# AM13E23219 register map
Vendor: Texas Instruments; File version: 1.0
CPU: CM33 r0p1, little endian, MPU, FPU, VTOR, 4 interrupt priority bits
Registers are 32-bit, read-write, reset 0x0 unless marked. A register's access mark holds for its fields unless they carry their own. Offsets are from the block's base; [hi:lo] are bit positions; lines under a group give offsets from that group; {n}, {i} and the like mark numbered series; 'fields as' and 'values as' point back to an identical list.

## ETPWM0 — EPWM module
Base 0x400B4000
Same registers: ETPWM1 0x400B5000, ETPWM2 0x400B6000, ETPWM3 0x400B7000, ETPWM4 0x400B8000, ETPWM5 0x400B9000
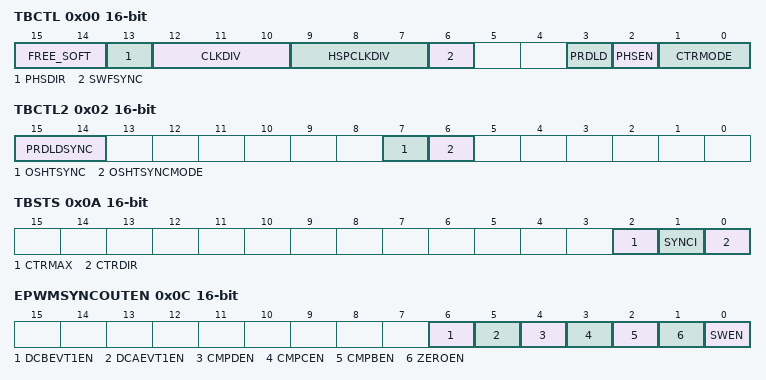
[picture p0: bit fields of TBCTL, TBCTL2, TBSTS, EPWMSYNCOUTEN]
0x00 TBCTL 16-bit — Time Base Control Register
  [15:14] FREE_SOFT — Emulation Mode Bits
  [13] PHSDIR — Phase Direction Bit
  [12:10] CLKDIV — Time Base Clock Pre-scaler
  [9:7] HSPCLKDIV — High Speed TBCLK Pre-scaler
  [6] SWFSYNC — Software Force Sync Pulse
  [3] PRDLD — Active Period Load
  [2] PHSEN — Phase Load Enable
  [1:0] CTRMODE — Counter Mode
0x02 TBCTL2 16-bit — Time Base Control Register 2
  [15:14] PRDLDSYNC — PRD Shadow to Active Load on SYNC Event
  [7] OSHTSYNC — One shot sync
  [6] OSHTSYNCMODE — One shot sync mode
0x06 EPWMSYNCINSEL 16-bit — EPWMxSYNCIN Source Select Register
  [4:0] SEL — EPWMxSYNCI source select
0x08 TBCTR 16-bit access not given — Time Base Counter Register
0x0A TBSTS 16-bit access per field — Time Base Status Register
  [2] CTRMAX rw — Counter Max Latched Status
  [1] SYNCI rw — External Input Sync Status
  [0] CTRDIR ro — Counter Direction Status
0x0C EPWMSYNCOUTEN 16-bit — EPWMxSYNCOUT Source Enable Register
  [6] DCBEVT1EN — EPWMxSYNCO Digital Compare B Event 1 Sync Enable
  [5] DCAEVT1EN — EPWMxSYNCO Digital Compare A Event 1 Sync Enable
  [4] CMPDEN — EPWMxSYNCO Compare D Event Enable
  [3] CMPCEN — EPWMxSYNCO Compare C Event Enable
  [2] CMPBEN — EPWMxSYNCO Compare B Event Enable
  [1] ZEROEN — EPWMxSYNCO Zero Count Event Enable
  [0] SWEN — EPWMxSYNCO Software Force Enable
0x0E TBCTL3 16-bit — Time Base Control Register 3
  [0] OSSFRCEN — One Shot Sync Force Enable
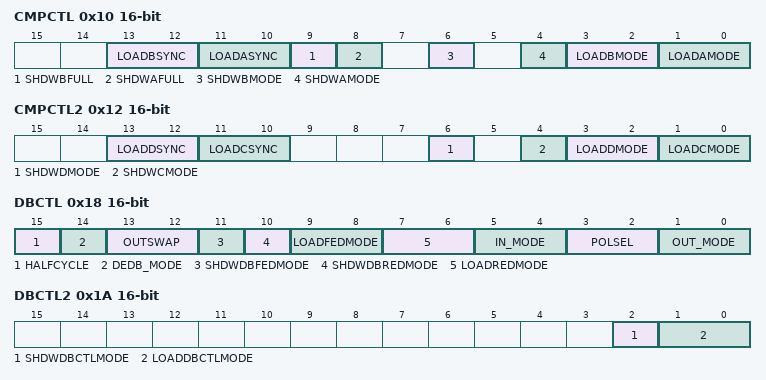
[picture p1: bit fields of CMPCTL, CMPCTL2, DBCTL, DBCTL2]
0x10 CMPCTL 16-bit access per field — Counter Compare Control Register
  [13:12] LOADBSYNC rw — Active Compare B Load on SYNC
  [11:10] LOADASYNC rw — Active Compare A Load on SYNC
  [9] SHDWBFULL ro — Compare B Shadow Register Full Status
  [8] SHDWAFULL ro — Compare A Shadow Register Full Status
  [6] SHDWBMODE rw — Compare B Register Block Operating Mode
  [4] SHDWAMODE rw — Compare A Register Block Operating Mode
  [3:2] LOADBMODE rw — Active Compare B Load
  [1:0] LOADAMODE rw — Active Compare A Load
0x12 CMPCTL2 16-bit — Counter Compare Control Register 2
  [13:12] LOADDSYNC — Active Compare D Load on SYNC
  [11:10] LOADCSYNC — Active Compare C Load on SYNC
  [6] SHDWDMODE — Compare D Block Operating Mode
  [4] SHDWCMODE — Compare C Block Operating Mode
  [3:2] LOADDMODE — Active Compare D load
  [1:0] LOADCMODE — Active Compare C Load
0x18 DBCTL 16-bit — Dead-Band Generator Control Register
  [15] HALFCYCLE — Half Cycle Clocking Enable
  [14] DEDB_MODE — Dead Band Dual-Edge B Mode Control
  [13:12] OUTSWAP — Dead Band Output Swap Control
  [11] SHDWDBFEDMODE — DBFED Block Operating Mode
  [10] SHDWDBREDMODE — DBRED Block Operating Mode
  [9:8] LOADFEDMODE — Active DBFED Load Mode
  [7:6] LOADREDMODE — Active DBRED Load Mode
  [5:4] IN_MODE — Dead Band Input Select Mode Control
  [3:2] POLSEL — Polarity Select Control
  [1:0] OUT_MODE — Dead Band Output Mode Control
0x1A DBCTL2 16-bit — Dead-Band Generator Control Register 2
  [2] SHDWDBCTLMODE — DBCTL Load mode Select
  [1:0] LOADDBCTLMODE — DBCTL Load from Shadow Mode Select
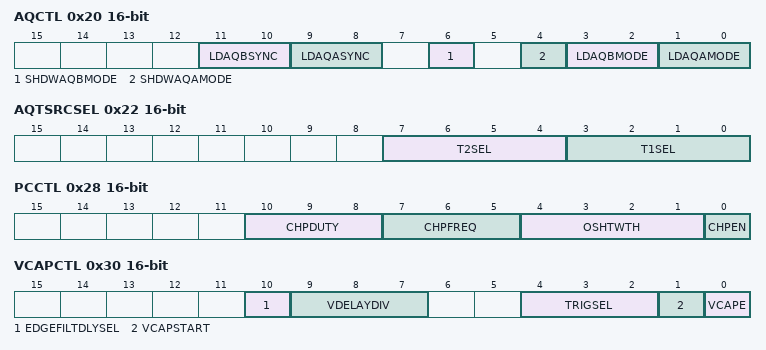
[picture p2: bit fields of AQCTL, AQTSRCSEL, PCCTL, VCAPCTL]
0x20 AQCTL 16-bit — Action Qualifier Control Register
  [11:10] LDAQBSYNC — AQCTLB Register Load on SYNC
  [9:8] LDAQASYNC — AQCTLA Register Load on SYNC
  [6] SHDWAQBMODE — Action Qualifier B Operating Mode
  [4] SHDWAQAMODE — Action Qualifer A Operating Mode
  [3:2] LDAQBMODE — Action Qualifier B Load Select
  [1:0] LDAQAMODE — Action Qualifier A Load Select
0x22 AQTSRCSEL 16-bit — Action Qualifier Trigger Event Source Select Register
  [7:4] T2SEL — T2 Event Source Select Bits
  [3:0] T1SEL — T1 Event Source Select Bits
0x28 PCCTL 16-bit — PWM Chopper Control Register
  [10:8] CHPDUTY — Chopping clock Duty cycle
  [7:5] CHPFREQ — Chopping clock frequency
  [4:1] OSHTWTH — One-shot pulse width
  [0] CHPEN — PWM chopping enable
0x30 VCAPCTL 16-bit — Valley Capture Control Register
  [10] EDGEFILTDLYSEL — Valley Switching Mode Delay Select
  [9:7] VDELAYDIV — Valley Delay Mode Divide Enable
  [4:2] TRIGSEL — Capture Trigger Select
  [1] VCAPSTART — Valley Capture Start
  [0] VCAPE — Valley Capture mode
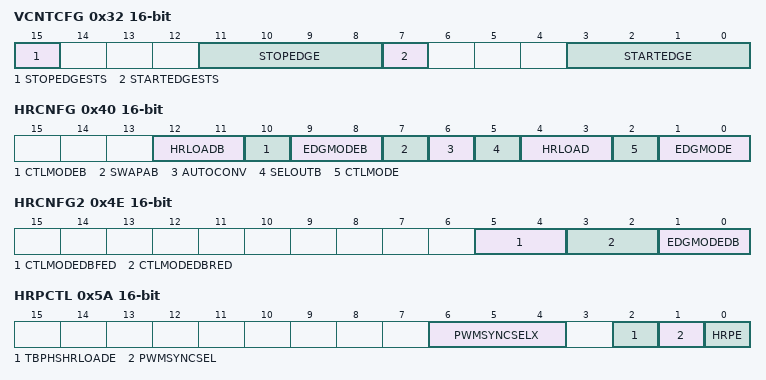
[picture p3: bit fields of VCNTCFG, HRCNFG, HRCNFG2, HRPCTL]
0x32 VCNTCFG 16-bit access per field — Valley Counter Config Register
  [15] STOPEDGESTS ro — Stop Edge Status Bit
  [11:8] STOPEDGE rw — Counter Start Edge Selection
  [7] STARTEDGESTS ro — Start Edge Status Bit
  [3:0] STARTEDGE rw — Counter Start Edge Selection
0x40 HRCNFG 16-bit — HRPWM Configuration Register
  [12:11] HRLOADB — ePWMxB Shadow Mode Select Bits
  [10] CTLMODEB — ePWMxB Control Mode Select Bits
  [9:8] EDGMODEB — ePWMxB Edge Mode Select Bits
  [7] SWAPAB — Swap EPWMA and EPWMB Outputs Bit
  [6] AUTOCONV — Autoconversion Bit
  [5] SELOUTB — EPWMB Output Selection Bit
  [4:3] HRLOAD — ePWMxA Shadow Mode Select Bits
  [2] CTLMODE — ePWMxA Control Mode Select Bits
  [1:0] EDGMODE — ePWMxA Edge Mode Select Bits
0x42 HRPWR 16-bit — HRPWM Power Register
  [15] CALPWRON — Calibration Power On
0x4C HRMSTEP 16-bit — HRPWM MEP Step Register
  [7:0] HRMSTEP — High Resolution Micro Step Value
0x4E HRCNFG2 16-bit — HRPWM Configuration 2 Register
  [5:4] CTLMODEDBFED — DBFED Control Mode Select Bits
  [3:2] CTLMODEDBRED — DBRED Control Mode Select Bits
  [1:0] EDGMODEDB — Dead-Band Edge-Mode Select Bits
0x5A HRPCTL 16-bit — High Resolution Period Control Register
  [6:4] PWMSYNCSELX — EPWMSYNCPER Extended Source Select Bit:
  [2] TBPHSHRLOADE — TBPHSHR Load Enable
  [1] PWMSYNCSEL — EPWMSYNCPER Source Select
  [0] HRPE — High Resolution Period Enable
0x5C TRREM 16-bit — HRPWM High Resolution Remainder Register
  [10:0] TRREM — HRPWM Remainder Bits
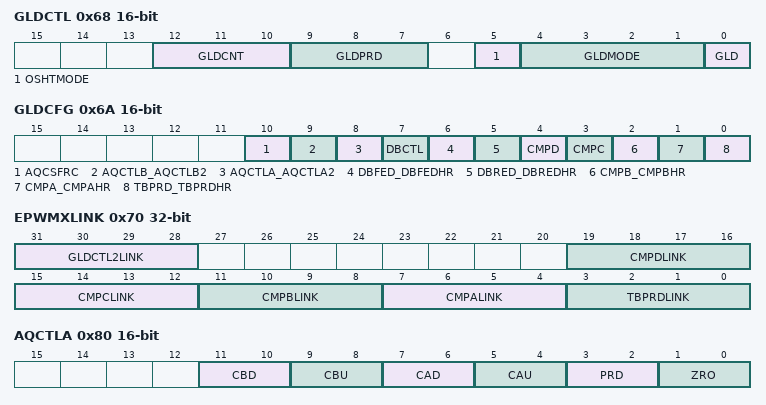
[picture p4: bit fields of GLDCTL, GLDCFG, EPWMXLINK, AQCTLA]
0x68 GLDCTL 16-bit access per field — Global PWM Load Control Register
  [12:10] GLDCNT ro — Global Load Strobe Counter Register
  [9:7] GLDPRD rw — Global Load Strobe Period Select Register
  [5] OSHTMODE rw — One Shot Load mode control bit
  [4:1] GLDMODE rw — Shadow to Active Global Load Pulse Selection
  [0] GLD rw — Global Shadow to Active load event control
0x6A GLDCFG 16-bit — Global PWM Load Config Register
  [10] AQCSFRC — Global load event configuration for AQCSFRC
  [9] AQCTLB_AQCTLB2 — Global load event configuration for AQCTLB/B2
  [8] AQCTLA_AQCTLA2 — Global load event configuration for AQCTLA/A2
  [7] DBCTL — Global load event configuration for DBCTL
  [6] DBFED_DBFEDHR — Global load event configuration for DBFED:DBFEDHR
  [5] DBRED_DBREDHR — Global load event configuration for DBRED:DBREDHR
  [4] CMPD — Global load event configuration for CMPD
  [3] CMPC — Global load event configuration for CMPC
  [2] CMPB_CMPBHR — Global load event configuration for CMPB:CMPBHR
  [1] CMPA_CMPAHR — Global load event configuration for CMPA:CMPAHR
  [0] TBPRD_TBPRDHR — Global load event configuration for TBPRD:TBPRDHR
0x70 EPWMXLINK
  [31:28] GLDCTL2LINK
  [19:16] CMPDLINK
  [15:12] CMPCLINK
  [11:8] CMPBLINK — CMPB:CMPBHR Link
  [7:4] CMPALINK — CMPA:CMPAHR Link
  [3:0] TBPRDLINK — TBPRD:TBPRDHR Link
0x80 AQCTLA 16-bit — Action Qualifier Control Register For Output A
  [11:10] CBD — Action Counter = Compare B Down
  [9:8] CBU — Action Counter = Compare B Up
  [7:6] CAD — Action Counter = Compare A Down
  [5:4] CAU — Action Counter = Compare A Up
  [3:2] PRD — Action Counter = Period
  [1:0] ZRO — Action Counter = Zero
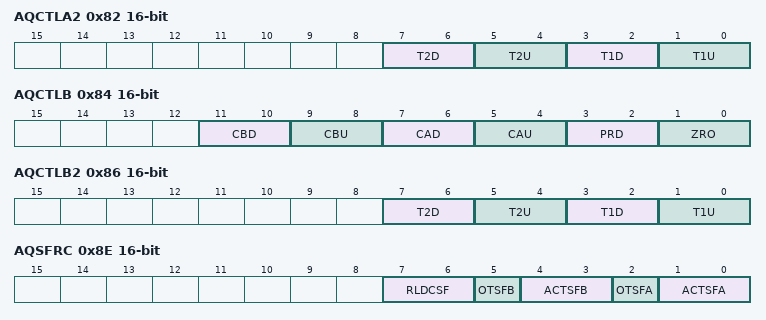
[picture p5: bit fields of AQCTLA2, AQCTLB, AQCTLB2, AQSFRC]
0x82 AQCTLA2 16-bit — Additional Action Qualifier Control Register For Output A
  [7:6] T2D — Action when event occurs on T2 in DOWN-Count
  [5:4] T2U — Action when event occurs on T2 in UP-Count
  [3:2] T1D — Action when event occurs on T1 in DOWN-Count
  [1:0] T1U — Action when event occurs on T1 in UP-Count
0x84 AQCTLB 16-bit — Action Qualifier Control Register For Output B
  fields as AQCTLA
0x86 AQCTLB2 16-bit — Additional Action Qualifier Control Register For Output B
  fields as AQCTLA2
0x8E AQSFRC 16-bit — Action Qualifier Software Force Register
  [7:6] RLDCSF — Reload from Shadow Options
  [5] OTSFB — One-time SW Force A Output
  [4:3] ACTSFB — Action when One-time SW Force B Invoked
  [2] OTSFA — One-time SW Force A Output
  [1:0] ACTSFA — Action when One-time SW Force A Invoked
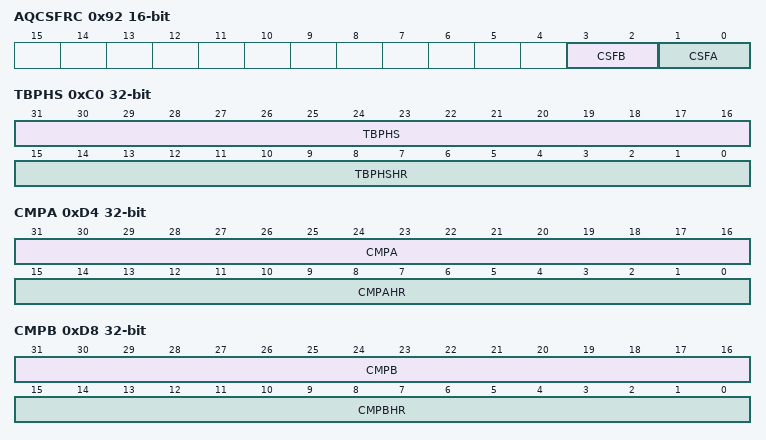
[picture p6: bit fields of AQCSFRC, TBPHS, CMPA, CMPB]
0x92 AQCSFRC 16-bit — Action Qualifier Continuous S/W Force Register
  [3:2] CSFB — Continuous Software Force on output B
  [1:0] CSFA — Continuous Software Force on output A
0xA0 DBREDHR 16-bit — Dead-Band Generator Rising Edge Delay High Resolution Mirror Register
  [15:9] DBREDHR — DBREDHR High Resolution Bits
0xA2 DBRED 16-bit — Dead-Band Generator Rising Edge Delay High Resolution Mirror Register
  [13:0] DBRED — Rising edge delay value
0xA4 DBFEDHR 16-bit — Dead-Band Generator Falling Edge Delay High Resolution Register
  [15:9] DBFEDHR — DBFEDHR High Resolution Bits
0xA6 DBFED 16-bit — Dead-Band Generator Falling Edge Delay Count Register
  [13:0] DBFED — Falling edge delay value
0xC0 TBPHS — Time Base Phase High
  [31:16] TBPHS — Phase Offset Register
  [15:0] TBPHSHR — Extension Register for HRPWM Phase (8-bits)
0xC4 TBPRDHR 16-bit — Time Base Period High Resolution Register
  [15:8] TBPRDHR — High res Time base period register
0xC6 TBPRD 16-bit access not given — Time Base Period Register
0xD4 CMPA — Counter Compare A Register
  [31:16] CMPA — Compare A Register
  [15:0] CMPAHR — Compare A HRPWM Extension Register
0xD8 CMPB — Compare B Register
  [31:16] CMPB — Compare B Register
  [15:0] CMPBHR — Compare B High Resolution Bits
0xDE CMPC 16-bit access not given — Counter Compare C Register
0xE2 CMPD 16-bit access not given — Counter Compare D Register
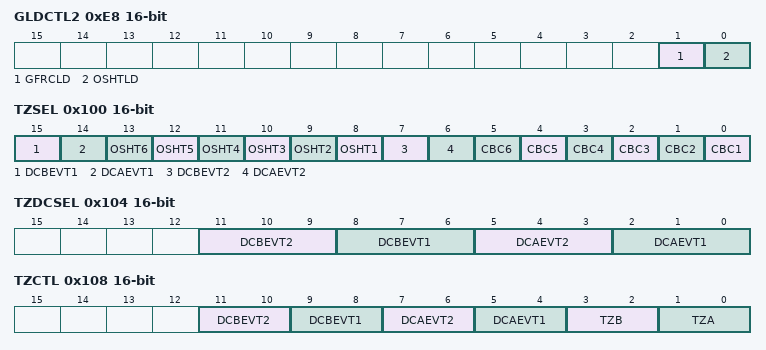
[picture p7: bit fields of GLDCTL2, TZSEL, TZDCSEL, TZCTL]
0xE8 GLDCTL2 16-bit — Global PWM Load Control Register 2
  [1] GFRCLD — Force reload event in one shot mode
  [0] OSHTLD — Enable reload event in one shot mode
0xEE SWVDELVAL 16-bit access not given — Software Valley Mode Delay Register
0x100 TZSEL 16-bit — Trip Zone Select Register
  [15] DCBEVT1 — One-shot DCBEVT1 select
  [14] DCAEVT1 — One-shot DCAEVT1 select
  [n+7] OSHT{n} (n=1..6) — One-shot TZ{n} select
  [7] DCBEVT2 — DCBEVT2 CBC select
  [6] DCAEVT2 — DCAEVT2 CBC select
  [n-1] CBC{n} (n=1..6) — TZ{n} CBC select
0x104 TZDCSEL 16-bit — Trip Zone Digital Comparator Select Register
  [11:9] DCBEVT2 — Digital Compare Output B Event 2
  [8:6] DCBEVT1 — Digital Compare Output B Event 1
  [5:3] DCAEVT2 — Digital Compare Output A Event 2
  [2:0] DCAEVT1 — Digital Compare Output A Event 1
0x108 TZCTL 16-bit — Trip Zone Control Register
  [11:10] DCBEVT2 — EPWMxB action on DCBEVT2
  [9:8] DCBEVT1 — EPWMxB action on DCBEVT1
  [7:6] DCAEVT2 — EPWMxA action on DCAEVT2
  [5:4] DCAEVT1 — EPWMxA action on DCAEVT1
  [3:2] TZB — TZ1 to TZ6 Trip Action On EPWMxB
  [1:0] TZA — TZ1 to TZ6 Trip Action On EPWMxA
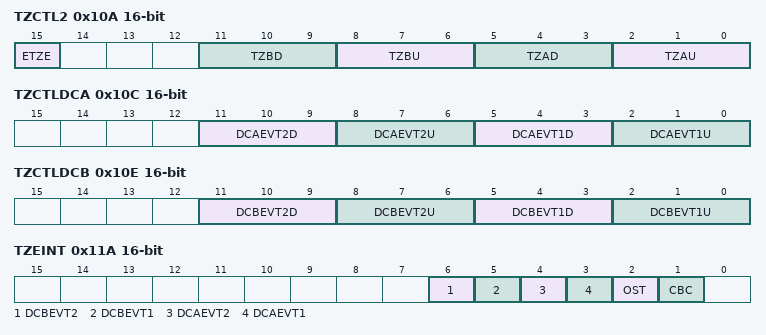
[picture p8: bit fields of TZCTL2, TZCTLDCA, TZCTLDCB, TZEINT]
0x10A TZCTL2 16-bit — Additional Trip Zone Control Register
  [15] ETZE — TZCTL2 Enable
  [11:9] TZBD — Trip Action On EPWMxB while Count direction is DOWN
  [8:6] TZBU — Trip Action On EPWMxB while Count direction is UP
  [5:3] TZAD — Trip Action On EPWMxA while Count direction is DOWN
  [2:0] TZAU — Trip Action On EPWMxA while Count direction is UP
0x10C TZCTLDCA 16-bit — Trip Zone Control Register Digital Compare A
  [11:9] DCAEVT2D — DCAEVT2 Action On EPWMxA while Count direction is DOWN
  [8:6] DCAEVT2U — DCAEVT2 Action On EPWMxA while Count direction is UP
  [5:3] DCAEVT1D — DCAEVT1 Action On EPWMxA while Count direction is DOWN
  [2:0] DCAEVT1U — DCAEVT1 Action On EPWMxA while Count direction is UP
0x10E TZCTLDCB 16-bit — Trip Zone Control Register Digital Compare B
  [11:9] DCBEVT2D — DCBEVT2 Action On EPWMxA while Count direction is DOWN
  [8:6] DCBEVT2U — DCBEVT2 Action On EPWMxA while Count direction is UP
  [5:3] DCBEVT1D — DCBEVT1 Action On EPWMxA while Count direction is DOWN
  [2:0] DCBEVT1U — DCBEVT1 Action On EPWMxA while Count direction is UP
0x11A TZEINT 16-bit — Trip Zone Enable Interrupt Register
  [6] DCBEVT2 — Digital Compare B Event 2 Int Enable
  [5] DCBEVT1 — Digital Compare B Event 1 Int Enable
  [4] DCAEVT2 — Digital Compare A Event 2 Int Enable
  [3] DCAEVT1 — Digital Compare A Event 1 Int Enable
  [2] OST — Trip Zones One Shot Int Enable
  [1] CBC — Trip Zones Cycle By Cycle Int Enable
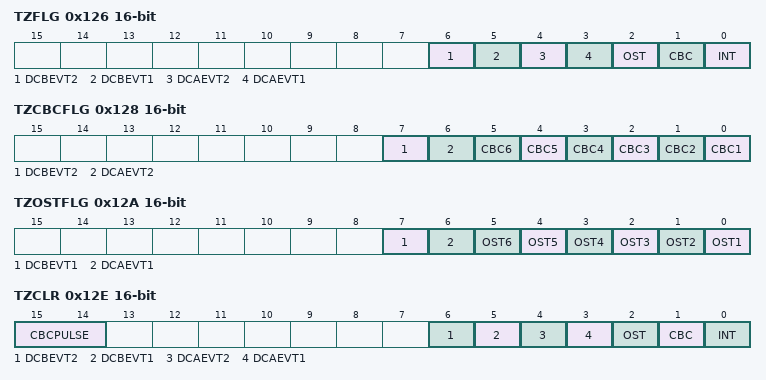
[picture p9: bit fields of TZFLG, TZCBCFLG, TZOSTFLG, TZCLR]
0x126 TZFLG 16-bit ro — Trip Zone Flag Register
  [6] DCBEVT2 — Digital Compare B Event 2 Flag
  [5] DCBEVT1 — Digital Compare B Event 1 Flag
  [4] DCAEVT2 — Digital Compare A Event 2 Flag
  [3] DCAEVT1 — Digital Compare A Event 1 Flag
  [2] OST — Trip Zones One Shot Flag
  [1] CBC — Trip Zones Cycle By Cycle Flag
  [0] INT — Global Int Status Flag
0x128 TZCBCFLG 16-bit ro — Trip Zone CBC Flag Register
  [7] DCBEVT2 — Latched Status Flag for Digital Compare Output B Event 2
  [6] DCAEVT2 — Latched Status Flag for Digital Compare Output A Event 2
  [n-1] CBC{n} (n=1..6) — Latched Status Flag for CBC{n} Trip Latch
0x12A TZOSTFLG 16-bit ro — Trip Zone OST Flag Register
  [7] DCBEVT1 — Latched Status Flag for Digital Compare Output B Event 1
  [6] DCAEVT1 — Latched Status Flag for Digital Compare Output A Event 1
  [n-1] OST{n} (n=1..6) — Latched Status Flag for OST{n} Trip Latch
0x12E TZCLR 16-bit — Trip Zone Clear Register
  [15:14] CBCPULSE — Clear Pulse for CBC Trip Latch
  [6] DCBEVT2 — DCBEVT2 Flag Clear
  [5] DCBEVT1 — DCBEVT1 Flag Clear
  [4] DCAEVT2 — DCAEVT2 Flag Clear
  [3] DCAEVT1 — DCAVET1 Flag Clear
  [2] OST — One-Shot Flag Clear
  [1] CBC — Cycle-By-Cycle Flag Clear
  [0] INT — Global Interrupt Clear Flag
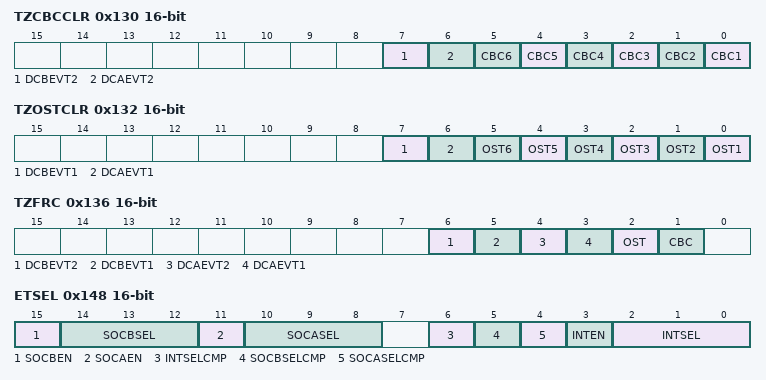
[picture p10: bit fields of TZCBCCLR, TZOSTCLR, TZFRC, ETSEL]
0x130 TZCBCCLR 16-bit — Trip Zone CBC Clear Register
  [7] DCBEVT2 — Clear Flag for DCBEVT2 selected for CBC
  [6] DCAEVT2 — Clear Flag forDCAEVT2 selected for CBC
  [n-1] CBC{n} (n=1..6) — Clear Flag for Cycle-By-Cycle (CBC{n}) Trip Latch
0x132 TZOSTCLR 16-bit — Trip Zone OST Clear Register
  [7] DCBEVT1 — Clear Flag for DCBEVT1 selected for OST
  [6] DCAEVT1 — Clear Flag for DCAEVT1 selected for OST
  [n-1] OST{n} (n=1..6) — Clear Flag for Oneshot (OST{n}) Trip Latch
0x136 TZFRC 16-bit — Trip Zone Force Register
  [6] DCBEVT2 — Force Digital Compare B Event 2
  [5] DCBEVT1 — Force Digital Compare B Event 1
  [4] DCAEVT2 — Force Digital Compare A Event 2
  [3] DCAEVT1 — Force Digital Compare A Event 1
  [2] OST — Force Trip Zones One Shot Event
  [1] CBC — Force Trip Zones Cycle By Cycle Event
0x148 ETSEL 16-bit — Event Trigger Selection Register
  [15] SOCBEN — Start of Conversion B Enable
  [14:12] SOCBSEL — Start of Conversion B Select
  [11] SOCAEN — Start of Conversion A Enable
  [10:8] SOCASEL — Start of Conversion A Select
  [6] INTSELCMP — EPWMxINT Compare Select
  [5] SOCBSELCMP — EPWMxSOCB Compare Select
  [4] SOCASELCMP — EPWMxSOCA Compare Select
  [3] INTEN — EPWMxINTn Enable
  [2:0] INTSEL — EPWMxINTn Select
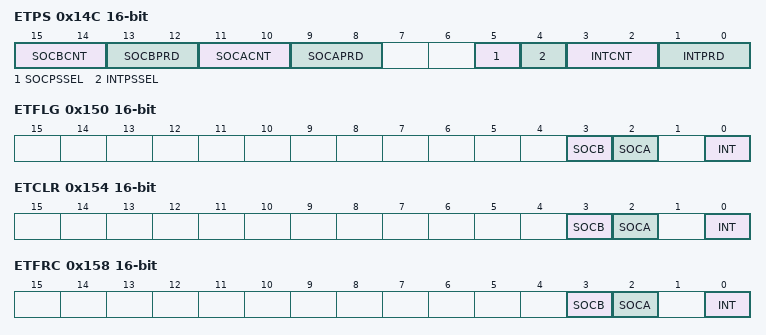
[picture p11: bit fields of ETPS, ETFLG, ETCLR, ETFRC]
0x14C ETPS 16-bit access per field — Event Trigger Pre-Scale Register
  [15:14] SOCBCNT ro — EPWMxSOCB Counter
  [13:12] SOCBPRD rw — EPWMxSOCB Period Select
  [11:10] SOCACNT ro — EPWMxSOCA Counter Register
  [9:8] SOCAPRD rw — EPWMxSOCA Period Select
  [5] SOCPSSEL rw — EPWMxSOC A/B Pre-Scale Selection Bits
  [4] INTPSSEL rw — EPWMxINTn Pre-Scale Selection Bits
  [3:2] INTCNT ro — EPWMxINTn Counter Register
  [1:0] INTPRD rw — EPWMxINTn Period Select
0x150 ETFLG 16-bit ro — Event Trigger Flag Register
  [3] SOCB — EPWMxSOCB Flag
  [2] SOCA — EPWMxSOCA Flag
  [0] INT — EPWMxINTn Flag
0x154 ETCLR 16-bit — Event Trigger Clear Register
  [3] SOCB — EPWMxSOCB Clear
  [2] SOCA — EPWMxSOCA Clear
  [0] INT — EPWMxINTn Clear
0x158 ETFRC 16-bit — Event Trigger Force Register
  [3] SOCB — EPWMxSOCB Force
  [2] SOCA — EPWMxSOCA Force
  [0] INT — EPWMxINTn Force
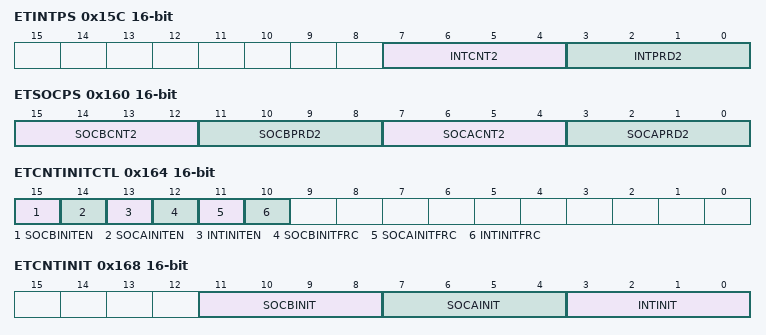
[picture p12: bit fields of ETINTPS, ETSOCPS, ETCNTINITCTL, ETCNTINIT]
0x15C ETINTPS 16-bit access per field — Event-Trigger Interrupt Pre-Scale Register
  [7:4] INTCNT2 ro — EPWMxINTn Counter Register
  [3:0] INTPRD2 rw — EPWMxINTn Period Select
0x160 ETSOCPS 16-bit access per field — Event-Trigger SOC Pre-Scale Register
  [15:12] SOCBCNT2 ro — EPWMxSOCB Counter Register
  [11:8] SOCBPRD2 rw — EPWMxSOCB Period Select
  [7:4] SOCACNT2 ro — EPWMxSOCA Counter Register
  [3:0] SOCAPRD2 rw — EPWMxSOCA Period Select
0x164 ETCNTINITCTL 16-bit — Event-Trigger Counter Initialization Control Register
  [15] SOCBINITEN — EPWMxSOCB Counter Initialization Enable
  [14] SOCAINITEN — EPWMxSOCA Counter Initialization Enable
  [13] INTINITEN — EPWMxINT Counter Initialization Enable
  [12] SOCBINITFRC — EPWMxSOCB Counter Initialization Force
  [11] SOCAINITFRC — EPWMxSOCA Counter Initialization Force
  [10] INTINITFRC — EPWMxINT Counter Initialization Force
0x168 ETCNTINIT 16-bit — Event-Trigger Counter Initialization Register
  [11:8] SOCBINIT — EPWMxSOCB Counter Initialization Bits
  [7:4] SOCAINIT — EPWMxSOCA Counter Initialization Bits
  [3:0] INTINIT — EPWMxINT Counter Initialization Bits
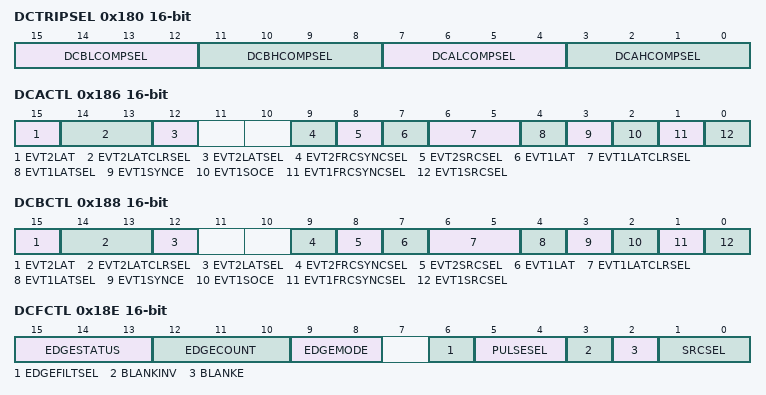
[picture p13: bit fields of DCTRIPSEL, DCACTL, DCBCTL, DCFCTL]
0x180 DCTRIPSEL 16-bit — Digital Compare Trip Select Register
  [15:12] DCBLCOMPSEL — Digital Compare B Low COMP Input Select
  [11:8] DCBHCOMPSEL — Digital Compare B High COMP Input Select
  [7:4] DCALCOMPSEL — Digital Compare A Low COMP Input Select
  [3:0] DCAHCOMPSEL — Digital Compare A High COMP Input Select
0x186 DCACTL 16-bit access per field — Digital Compare A Control Register
  [15] EVT2LAT ro — Indicates the status of DCAEVT2LAT signal.
  [14:13] EVT2LATCLRSEL rw — DCAEVT2 Latched clear source select
  [12] EVT2LATSEL rw — DCAEVT2 Latched signal select
  [9] EVT2FRCSYNCSEL rw — DCAEVT2 Force Sync Signal
  [8] EVT2SRCSEL rw — DCAEVT2 Source Signal
  [7] EVT1LAT ro — Indicates the status of DCAEVT1LAT signal.
  [6:5] EVT1LATCLRSEL rw — DCAEVT1 Latched clear source select
  [4] EVT1LATSEL rw — DCAEVT1 Latched signal select
  [3] EVT1SYNCE rw — DCAEVT1 SYNC Enable
  [2] EVT1SOCE rw — DCAEVT1 SOC Enable
  [1] EVT1FRCSYNCSEL rw — DCAEVT1 Force Sync Signal
  [0] EVT1SRCSEL rw — DCAEVT1 Source Signal
0x188 DCBCTL 16-bit access per field — Digital Compare B Control Register
  [15] EVT2LAT ro — Indicates the status of DCBEVT2LAT signal.
  [14:13] EVT2LATCLRSEL rw — DCBEVT2 Latched clear source select
  [12] EVT2LATSEL rw — DCBEVT2 Latched signal select
  [9] EVT2FRCSYNCSEL rw — DCBEVT2 Force Sync Signal
  [8] EVT2SRCSEL rw — DCBEVT2 Source Signal
  [7] EVT1LAT ro — Indicates the status of DCBEVT1LAT signal.
  [6:5] EVT1LATCLRSEL rw — DCBEVT1 Latched clear source select
  [4] EVT1LATSEL rw — DCBEVT1 Latched signal select
  [3] EVT1SYNCE rw — DCBEVT1 SYNC Enable
  [2] EVT1SOCE rw — DCBEVT1 SOC Enable
  [1] EVT1FRCSYNCSEL rw — DCBEVT1 Force Sync Signal
  [0] EVT1SRCSEL rw — DCBEVT1 Source Signal
0x18E DCFCTL 16-bit access per field — Digital Compare Filter Control Register
  [15:13] EDGESTATUS ro
  [12:10] EDGECOUNT rw
  [9:8] EDGEMODE rw
  [6] EDGEFILTSEL rw — Edge Filter Select
  [5:4] PULSESEL rw — Pulse Select for Blanking & Capture Alignment
  [3] BLANKINV rw — Blanking Window Inversion
  [2] BLANKE rw — Blanking Enable/Disable
  [1:0] SRCSEL rw — Filter Block Signal Source Select
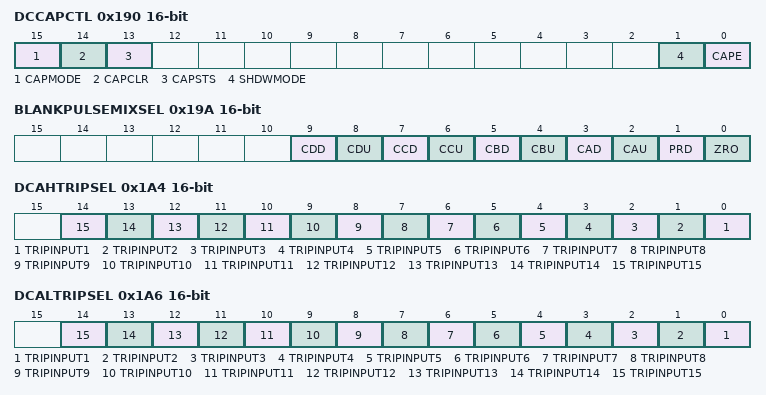
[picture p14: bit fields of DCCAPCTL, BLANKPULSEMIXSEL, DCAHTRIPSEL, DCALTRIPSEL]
0x190 DCCAPCTL 16-bit access per field — Digital Compare Capture Control Register
  [15] CAPMODE rw — Counter Capture Mode
  [14] CAPCLR rw — DC Capture Latched Status Clear Flag
  [13] CAPSTS ro — Latched Status Flag for Capture Event
  [1] SHDWMODE rw — Counter Capture Mode
  [0] CAPE rw — Counter Capture Enable
0x192 DCFOFFSET 16-bit access not given — Digital Compare Filter Offset Register
0x194 DCFOFFSETCNT 16-bit access not given — Digital Compare Filter Offset Counter Register
0x196 DCFWINDOW 16-bit access not given — Digital Compare Filter Window Register
0x198 DCFWINDOWCNT 16-bit access not given — Digital Compare Filter Window Counter Register
0x19A BLANKPULSEMIXSEL 16-bit — Blanking window trigger pulse select register
  [9] CDD — CMPD down-count match enable to BLANKPULSEMIX
  [8] CDU — CMPD up-count match enable to BLANKPULSEMIX
  [7] CCD — CMPC down-count match enable to BLANKPULSEMIX
  [6] CCU — CMPC up-count match enable to BLANKPULSEMIX
  [5] CBD — CMPB down-count match enable to BLANKPULSEMIX
  [4] CBU — CMPB up-count match enable to BLANKPULSEMIX
  [3] CAD — CMPA down-count match enable to BLANKPULSEMIX
  [2] CAU — CMPA up-count match enable to BLANKPULSEMIX
  [1] PRD — Period match enable to BLANKPULSEMIX
  [0] ZRO — Zero match enable to BLANKPULSEMIX
0x19E DCCAP 16-bit access not given — Digital Compare Counter Capture Register
0x1A4 DCAHTRIPSEL 16-bit — Digital Compare AH Trip Select
  [n-1] TRIPINPUT{n} (n=1..15) — Trip Input {n} Select to DCAH Mux
0x1A6 DCALTRIPSEL 16-bit — Digital Compare AL Trip Select
  [n-1] TRIPINPUT{n} (n=1..15) — Trip Input {n} Select to DCAL Mux
0x1A8 DCBHTRIPSEL 16-bit — Digital Compare BH Trip Select
  [n-1] TRIPINPUT{n} (n=1..15) — Trip Input {n} Select to DCBH Mux
0x1AA DCBLTRIPSEL 16-bit — Digital Compare BL Trip Select
  [n-1] TRIPINPUT{n} (n=1..15) — Trip Input {n} Select to DCBL Mux
0x1F4 EPWMLOCK access per field
  [31:16] KEY wo — Key which must be written for the write to take effect.
  [4] DCLOCK rw — Digital Compare Register Set Lock
  [3] TZCLRLOCK rw — TripZone Clear Register Set Lock
  [2] TZCFGLOCK rw — TripZone Register Set Lock
  [1] GLLOCK rw — Global Load Register Set Lock
  [0] HRLOCK rw — HRPWM Register Set Lock
0x1FA HWVDELVAL 16-bit access not given — Hardware Valley Mode Delay Register
0x1FC VCNTVAL 16-bit access not given — Hardware Valley Counter Register
0x404 PINCM group
  0x00 EXTCOMP1OUT — External comparator 1 output from GPIO pad to peripheral
    [30] GFLT — Glitch Filter Enable
      0=DISABLE (No internal glitch filter); 1=ENABLE (Use internal glitch filter)
    [29] SLEW — Reserved Slew Rate Control
      0=DISABLE (No Slew Rate Control); 1=ENABLE (Use Slew Rate Control)
    [28] WCOMP — Wake up compare value
      0=MATCH_ZERO (Match 0 will wake); 1=MATCH_ONE (Match 1 will wake)
    [27] WUEN — Wake up enable
      0=NO_WAKEUP (Wake up not enabled); 1=WAKEUP (Wake up enabled)
    [26] INV — Invert digital input/output relative to peripheral/GPIO
      0=NO_CHNG (Input and output are non-inverted); 1=CHNG (Input and output are inverted)
    [25] HIGHZ1 — High-Z instead of high output
      0=DRV_HIGH (Pin can be driven high); 1=DRV_HIZ (Pin is tri-stated instead of driven high)
    [24] HIGHZ0 — High-Z instead of low output
      0=DRV_LOW (Pin can be driven low); 1=DRV_HIZ (Pin is tri-stated instead of driven low)
    [22:20] DRV — Drive strength options
      0=STRENGTH_0 (Lowest drive strength); {v}=STRENGTH_{v} (Drive strength {v+1}/8) (v=1..6); 7=STRENGTH_7 (Highest drive strength)
    [19] HYSTEN — Hysteresis enable
      0=DIS_HYST (No hysteresis); 1=EN_HYST (Hysteresis on)
    [18] INENA — Input enable
      0=INP_DISABLE (Inputs 0 to connected core); 1=INP_ENABLE (Inputs IO pad value to connected core)
    [17] PIPU — Pull up enable
      0=NO_PULL_UP; 1=PULL_UP
    [16] PIPD — Pull down enable
      0=NO_PULL_DOWN; 1=PULL_DOWN
    [15:14] GSTATE — GPIO Channel State
      0=UNASSIGNED (G-Channel is in Unassigned State); 1=HANDOVER (G-Channel is in Handover State); 2=CONC_NOT_LOCKED (G-Channel is in Connected State and not Locked (That is F field is allowed to change without going back through Unassigned state)); 3=CONC_LOCKED (G-Channel is in Connected State and Locked (That is F field is not allowed to change to a different non-Zero value until both G and P channels go to Unassigned))
    [7:6] PSTATE — Peripheral-Analog Channel State
      0=UNASSIGNED (P-Channel is in Unassigned State); 1=HANDOVER (P-Channel is in Handover State); 2=CONC_NOT_LOCKED (P-Channel is in Connected State and not Locked (That is F field is allowed to change without going back through Unassigned state)); 3=CONC_LOCKED (P-Channel is in Connected State and Locked (That is F field is not allowed to change to a different non-Zero value until both G and P channels go to Unassigned))
  0x04 EXTCOMP2OUT — External comparator 2 output from GPIO pad to peripheral
    fields as PINCM.EXTCOMP1OUT
  0x08 EXTCOMP3OUT — External comparator 3 output from GPIO pad to peripheral
    fields as PINCM.EXTCOMP1OUT
  0x0C EXTTRIPIN4 — External trip input signal 4 from GPIO pad to peripheral
    fields as PINCM.EXTCOMP1OUT
  0x10 EXTTRIPIN5 — External trip input signal 5 from GPIO pad to peripheral
    fields as PINCM.EXTCOMP1OUT
  0x14 EXTTRIPIN6 — External trip input signal 6 from GPIO pad to peripheral
    fields as PINCM.EXTCOMP1OUT
  0x18 EXTTRIPIN7 — External trip input signal 7 from GPIO pad to peripheral
    fields as PINCM.EXTCOMP1OUT
  0x1C EXTTRIPIN8 — External trip input signal 8 from GPIO pad to peripheral
    fields as PINCM.EXTCOMP1OUT
  0x20 EXTTRIPIN12 — External trip input signal 12 from GPIO pad to peripheral
    fields as PINCM.EXTCOMP1OUT
  0x24 EXTTRIPIN13 — External trip input signal 13 from GPIO pad to peripheral
    fields as PINCM.EXTCOMP1OUT
  0x28 EXTTRIPIN14 — External trip input signal 14 from GPIO pad to peripheral
    fields as PINCM.EXTCOMP1OUT
  0x2C EXTTRIPIN15 — External trip input signal 15 from GPIO pad to peripheral
    fields as PINCM.EXTCOMP1OUT
  {0x30+4j} EXTSYNCIN{j} (j=0..30) — External synchronization input signal {j} from GPIO pad to peripheral
    fields as PINCM.EXTCOMP1OUT
  0xAC PWMPWMA — PWM A output signal going to GPIO mux for external pin
    fields as PINCM.EXTCOMP1OUT
  0xB0 PWMPWMB — PWM B output signal going to GPIO mux for external pin
    fields as PINCM.EXTCOMP1OUT
  0xB4 OTHPWMA — PWM A output signal
    fields as PINCM.EXTCOMP1OUT
  0xB8 OTHPWMB — PWM B output signal
    fields as PINCM.EXTCOMP1OUT
0x604 FUPDATE group
  0x00 EXTCOMP1OUT — FUPDATE version of EXTCOMP1OUT
    [27:2] IOADDR — IO Address. This is the address that corresponds to the SOC address[27:2] of the module IP instance specific IO signal in the "Full Write" subregion of the pinmux subregion.
    [1] LOCK — Sets lock bit
      0=NOEFFECT (Writing this value has no effect); 1=LOCK (Set channel lock bit)
    [0] GSEL — GPIO channel Select 0: Select the P-Channel for the F update 1: Select the G-Channel for the F update
      0=PCHAN (Select the P-Channel for the F update); 1=GCHAN (Select the G-Channel for the F update)
  0x04 EXTCOMP2OUT — FUPDATE version of EXTCOMP2OUT
    fields as FUPDATE.EXTCOMP1OUT
  0x08 EXTCOMP3OUT — FUPDATE version of EXTCOMP3OUT
    fields as FUPDATE.EXTCOMP1OUT
  0x0C EXTTRIPIN4 — FUPDATE version of EXTTRIPIN4
    fields as FUPDATE.EXTCOMP1OUT
  0x10 EXTTRIPIN5 — FUPDATE version of EXTTRIPIN5
    fields as FUPDATE.EXTCOMP1OUT
  0x14 EXTTRIPIN6 — FUPDATE version of EXTTRIPIN6
    fields as FUPDATE.EXTCOMP1OUT
  0x18 EXTTRIPIN7 — FUPDATE version of EXTTRIPIN7
    fields as FUPDATE.EXTCOMP1OUT
  0x1C EXTTRIPIN8 — FUPDATE version of EXTTRIPIN8
    fields as FUPDATE.EXTCOMP1OUT
  0x20 EXTTRIPIN12 — FUPDATE version of EXTTRIPIN12
    fields as FUPDATE.EXTCOMP1OUT
  0x24 EXTTRIPIN13 — FUPDATE version of EXTTRIPIN13
    fields as FUPDATE.EXTCOMP1OUT
  0x28 EXTTRIPIN14 — FUPDATE version of EXTTRIPIN14
    fields as FUPDATE.EXTCOMP1OUT
  0x2C EXTTRIPIN15 — FUPDATE version of EXTTRIPIN15
    fields as FUPDATE.EXTCOMP1OUT
  {0x30+4j} EXTSYNCIN{j} (j=0..30) — FUPDATE version of EXTSYNCIN{j}
    fields as FUPDATE.EXTCOMP1OUT
  0xAC PWMPWMA — FUPDATE version of PWMPWMA
    fields as FUPDATE.EXTCOMP1OUT
  0xB0 PWMPWMB — FUPDATE version of PWMPWMB
    fields as FUPDATE.EXTCOMP1OUT
  0xB4 OTHPWMA — FUPDATE version of OTHPWMA
    fields as FUPDATE.EXTCOMP1OUT
  0xB8 OTHPWMB — FUPDATE version of OTHPWMB
    fields as FUPDATE.EXTCOMP1OUT
